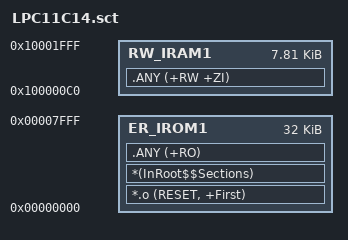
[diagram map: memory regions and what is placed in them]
; *************************************************************
; *** Scatter-Loading Description File generated by uVision ***
; *************************************************************

LR_IROM1 0x00000000 0x00008000  {    ; load region size_region
  ER_IROM1 0x00000000 0x00008000  {  ; load address = execution address
   *.o (RESET, +First)
   *(InRoot$$Sections)
   .ANY (+RO)
  }
  RW_IRAM1 0x100000C0 0x00001F40  {  ; RW data
   .ANY (+RW +ZI)
  }
}

;由于RAM的低地址的192个字节被用来存放中断向量表，因此这个区域不能被程序使用。
;程序必须避开这个区域的内存，所以地址起始由0x10000000改为0x100000C0。
;同理内存大小由0x00002000改为0x00001F40。
